# STM32U5Gx register map
File version: 1.0
CPU: CM33 r0p1, little endian, MPU, FPU, 4 interrupt priority bits
Registers are 32-bit, read-write, reset 0x0 unless marked. A register's access mark holds for its fields unless they carry their own. Offsets are from the block's base; [hi:lo] are bit positions; {n}, {i} and the like mark numbered series; 'fields as' and 'values as' point back to an identical list.

## JPEG — JPEG address block description
Base 0x4002A000
Same registers: SEC_JPEG 0x5002A000
0x00 JPEG_CONFR0 wo — JPEG codec control register
  [0] START — Start This bit start or stop the encoding or decoding process. Note: Reads always return 0.
    0=Stop/abort; 1=Start
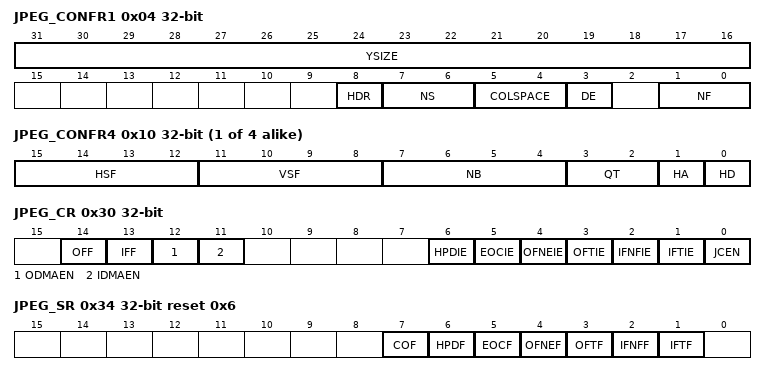
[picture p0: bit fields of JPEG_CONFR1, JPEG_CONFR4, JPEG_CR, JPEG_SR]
0x04 JPEG_CONFR1 — JPEG codec configuration register 1
  [31:16] YSIZE — Y Size This field defines the number of lines in source image.
  [8] HDR — Header processing This bit enables the header processing (generation/parsing).
    0=Disable; 1=Enable
  [7:6] NS — Number of components for scan This field defines the number of components minus 1 for scan header marker segment.
  [5:4] COLSPACE — Color space This filed defines the number of quantization tables minus 1 to insert in the output stream.
    0=Grayscale (1 quantization table); 1=YUV (2 quantization tables); 2=RGB (3 quantization tables); 3=CMYK (4 quantization tables)
  [3] DE — Codec operation as coder or decoder This bit selects the code or decode process
    0=Code; 1=Decode
  [1:0] NF — Number of color components This field defines the number of color components minus 1.
    0=Grayscale (1 color component); 1=- (2 color components); 2=YUV or RGB (3 color components); 3=CMYK (4 color components)
0x08 JPEG_CONFR2 — JPEG codec configuration register 2
  [25:0] NMCU — Number of MCUs For encoding: this field defines the number of MCU units minus 1 to encode. For decoding: this field indicates the number of complete MCU units minus 1 to be decoded (this field is updated after the JPEG header parsing). If the decoded image size has not a X or Y size multiple of 8 or 16 (depending on the sub-sampling process), the resulting incomplete or empty MCU must be added to this value to get the total number of MCUs generated.
0x0C JPEG_CONFR3 — JPEG codec configuration register 3
  [31:16] XSIZE — X size This field defines the number of pixels per line.
{0x0+4i} JPEG_CONFR{i} (i=4..7) — JPEG codec configuration register {i}
  [15:12] HSF — Horizontal sampling factor Horizontal sampling factor for component {i-4}.
  [11:8] VSF — Vertical sampling factor Vertical sampling factor for component {i-4}.
  [7:4] NB — Number of blocks Number of data units minus 1 that belong to a particular color in the MCU.
  [3:2] QT — Quantization table Selects quantization table used for component {i-4}.
    {v}=Quantization table {v} (v=0..3)
  [1] HA — Huffman AC Selects the Huffman table for encoding AC coefficients.
    0=Huffman AC table 0; 1=Huffman AC table 1
  [0] HD — Huffman DC Selects the Huffman table for encoding DC coefficients.
    0=Huffman DC table 0; 1=Huffman DC table 1
0x30 JPEG_CR access per field — JPEG control register
  [14] OFF wo — Output FIFO flush This bit flushes the output FIFO. Note: Reads always return 0.
    0=No effect; 1=Output FIFO is flushed
  [13] IFF wo — Input FIFO flush This bit flushes the input FIFO. Note: Reads always return 0.
    0=No effect; 1=Input FIFO is flushed
  [12] ODMAEN rw — Output DMA enable Enables DMA request generation for the output FIFO.
    0=Disabled; 1=Enabled
  [11] IDMAEN rw — Input DMA enable Enables DMA request generation for the input FIFO.
    0=Disabled; 1=Enabled
  [6] HPDIE rw — Header parsing done interrupt enable This bit enables interrupt generation upon the completion of the header parsing operation.
    0=Disabled; 1=Enabled
  [5] EOCIE rw — End of conversion interrupt enable This bit enables interrupt generation at the end of conversion.
    0=Disabled; 1=Enabled
  [4] OFNEIE rw — Output FIFO not empty interrupt enable This bit enables interrupt generation when the output FIFO is not empty.
    0=Disabled; 1=Enabled
  [3] OFTIE rw — Output FIFO threshold interrupt enable This bit enables interrupt generation when the output FIFO reaches a threshold.
    0=Disabled; 1=Enabled
  [2] IFNFIE rw — Input FIFO not full interrupt enable This bit enables interrupt generation when the input FIFO is not empty.
    0=Disabled; 1=Enabled
  [1] IFTIE rw — Input FIFO threshold interrupt enable This bit enables interrupt generation when the input FIFO reaches a threshold.
    0=Disabled; 1=Enabled
  [0] JCEN rw — JPEG core enable This bit enables the JPEG codec core.
    0=Disabled (internal registers are reset); 1=Enabled (internal registers are accessible)
0x34 JPEG_SR ro reset 0x6 — JPEG status register
  [7] COF — Codec operation flag This bit flags code/decode operation in progress.
    0=Not in progress; 1=In progress
  [6] HPDF — Header parsing done flag In decode mode, this bit flags the completion of header parsing and updating internal registers.
    0=Not completed; 1=Completed
  [5] EOCF — End of conversion flag This bit flags the completion of encode/decode process and data transfer to the output FIFO.
    0=Not completed; 1=Completed
  [4] OFNEF — Output FIFO not empty flag This bit flags that data is available in the output FIFO. This flag must not be considered when using DMA.
    0=Empty (data not available); 1=Not empty (data available)
  [3] OFTF — Output FIFO threshold flag This bit flags that the amount of data in the output FIFO reaches or exceeds a threshold. This flag must not be considered when using DMA.
    0=Below threshold; 1=At or above threshold
  [2] IFNFF — Input FIFO not full flag This bit flags that the input FIFO is not full (data can be written). This flag must not be considered when using DMA.
    0=Full; 1=Not full
  [1] IFTF — Input FIFO threshold flag This bit flags that the amount of data in the input FIFO is below a threshold. This flag must not be considered when using DMA.
    0=At or above threshold; 1=Below threshold
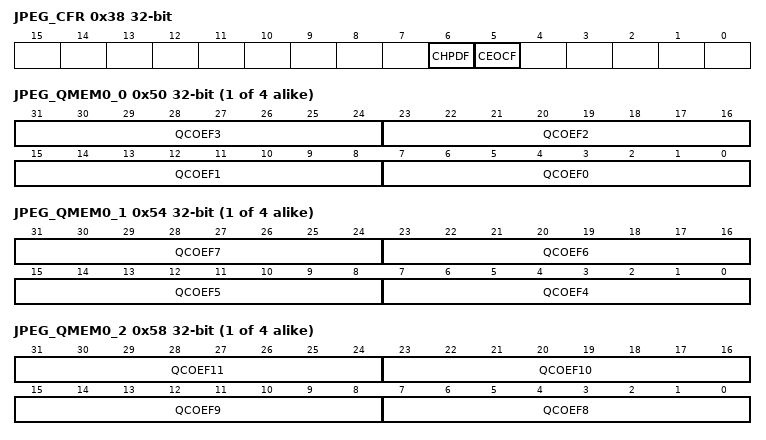
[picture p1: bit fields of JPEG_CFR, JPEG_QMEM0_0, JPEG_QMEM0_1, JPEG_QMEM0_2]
0x38 JPEG_CFR — JPEG clear flag register
  [6] CHPDF — Clear header parsing done flag Writing 1 clears the HPDF bit of the JPEG_SR register.
    0=No effect; 1=Clear
  [5] CEOCF — Clear end of conversion flag Writing 1 clears the ECF bit of the JPEG_SR register.
    0=No effect; 1=Clear
0x40 JPEG_DIR wo — JPEG data input register
  [31:0] DATAIN — Data input FIFO Input FIFO data register
0x44 JPEG_DOR ro — JPEG data output register
  [31:0] DATAOUT — Data output FIFO Output FIFO data register.
{0x50+0x40*i} JPEG_QMEM{i}_0 reset not defined (i=0..3) — JPEG quantization memory {i}
  [8n+7:8n] QCOEF{n} (n=0..3) — Quantization coefficient {n} 8-bit quantization coefficient.
{0x54+0x40*i} JPEG_QMEM{i}_1 reset not defined (i=0..3) — JPEG quantization memory {i}
  [8n-25:8n-32] QCOEF{n} (n=4..7) — Quantization coefficient {n} 8-bit quantization coefficient.
{0x58+0x40*i} JPEG_QMEM{i}_2 reset not defined (i=0..3) — JPEG quantization memory {i}
  [8n-57:8n-64] QCOEF{n} (n=8..11) — Quantization coefficient {n} 8-bit quantization coefficient.
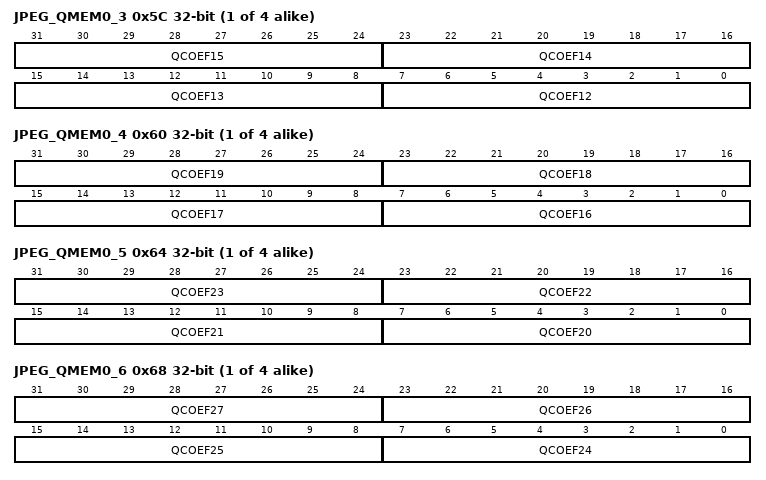
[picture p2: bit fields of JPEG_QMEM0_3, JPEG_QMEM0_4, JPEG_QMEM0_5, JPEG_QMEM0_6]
{0x5C+0x40*i} JPEG_QMEM{i}_3 reset not defined (i=0..3) — JPEG quantization memory {i}
  [8n-89:8n-96] QCOEF{n} (n=12..15) — Quantization coefficient {n} 8-bit quantization coefficient.
{0x60+0x40*i} JPEG_QMEM{i}_4 reset not defined (i=0..3) — JPEG quantization memory {i}
  [8n-121:8n-128] QCOEF{n} (n=16..19) — Quantization coefficient {n} 8-bit quantization coefficient.
{0x64+0x40*i} JPEG_QMEM{i}_5 reset not defined (i=0..3) — JPEG quantization memory {i}
  [8n-153:8n-160] QCOEF{n} (n=20..23) — Quantization coefficient {n} 8-bit quantization coefficient.
{0x68+0x40*i} JPEG_QMEM{i}_6 reset not defined (i=0..3) — JPEG quantization memory {i}
  [8n-185:8n-192] QCOEF{n} (n=24..27) — Quantization coefficient {n} 8-bit quantization coefficient.
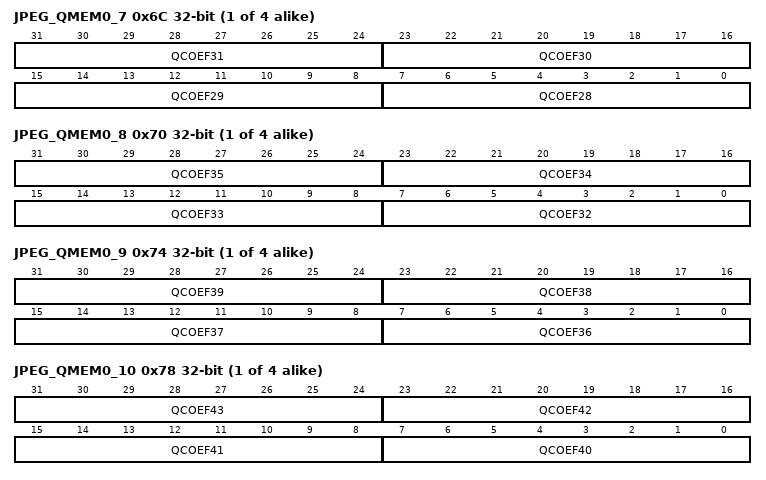
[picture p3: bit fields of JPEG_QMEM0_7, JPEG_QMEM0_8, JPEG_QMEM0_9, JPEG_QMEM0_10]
{0x6C+0x40*i} JPEG_QMEM{i}_7 reset not defined (i=0..3) — JPEG quantization memory {i}
  [8n-217:8n-224] QCOEF{n} (n=28..31) — Quantization coefficient {n} 8-bit quantization coefficient.
{0x70+0x40*i} JPEG_QMEM{i}_8 reset not defined (i=0..3) — JPEG quantization memory {i}
  [8n-249:8n-256] QCOEF{n} (n=32..35) — Quantization coefficient {n} 8-bit quantization coefficient.
{0x74+0x40*i} JPEG_QMEM{i}_9 reset not defined (i=0..3) — JPEG quantization memory {i}
  [8n-281:8n-288] QCOEF{n} (n=36..39) — Quantization coefficient {n} 8-bit quantization coefficient.
{0x78+0x40*i} JPEG_QMEM{i}_10 reset not defined (i=0..3) — JPEG quantization memory {i}
  [8n-313:8n-320] QCOEF{n} (n=40..43) — Quantization coefficient {n} 8-bit quantization coefficient.
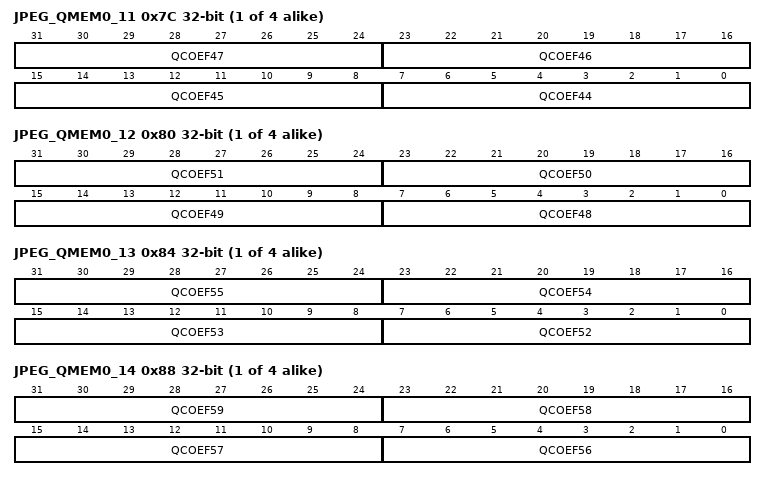
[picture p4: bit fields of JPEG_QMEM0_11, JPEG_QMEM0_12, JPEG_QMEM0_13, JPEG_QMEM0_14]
{0x7C+0x40*i} JPEG_QMEM{i}_11 reset not defined (i=0..3) — JPEG quantization memory {i}
  [8n-345:8n-352] QCOEF{n} (n=44..47) — Quantization coefficient {n} 8-bit quantization coefficient.
{0x80+0x40*i} JPEG_QMEM{i}_12 reset not defined (i=0..3) — JPEG quantization memory {i}
  [8n-377:8n-384] QCOEF{n} (n=48..51) — Quantization coefficient {n} 8-bit quantization coefficient.
{0x84+0x40*i} JPEG_QMEM{i}_13 reset not defined (i=0..3) — JPEG quantization memory {i}
  [8n-409:8n-416] QCOEF{n} (n=52..55) — Quantization coefficient {n} 8-bit quantization coefficient.
{0x88+0x40*i} JPEG_QMEM{i}_14 reset not defined (i=0..3) — JPEG quantization memory {i}
  [8n-441:8n-448] QCOEF{n} (n=56..59) — Quantization coefficient {n} 8-bit quantization coefficient.
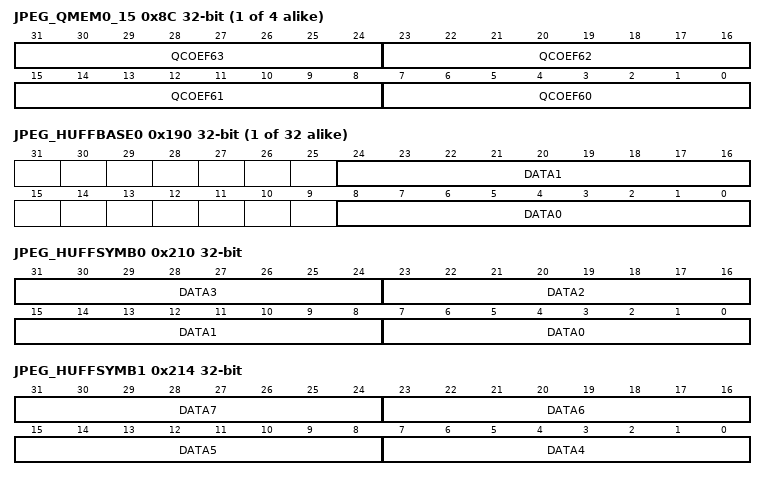
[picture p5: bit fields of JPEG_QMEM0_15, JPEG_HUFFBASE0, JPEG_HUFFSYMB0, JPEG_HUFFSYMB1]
{0x8C+0x40*i} JPEG_QMEM{i}_15 reset not defined (i=0..3) — JPEG quantization memory {i}
  [8n-473:8n-480] QCOEF{n} (n=60..63) — Quantization coefficient {n} 8-bit quantization coefficient.
{0x150+0x10*i} JPEG_HUFFMIN{i}_0 reset not defined (i=0..3) — JPEG Huffman min
  [31:0] DATA{i} — Minimum Huffman value 100-bit minimum Huffman value used internally by the JPEG decoder.
{0x154+0x10*i} JPEG_HUFFMIN{i}_1 reset not defined (i=0..3) — JPEG Huffman min
  fields as JPEG_HUFFMIN0_0
{0x158+0x10*i} JPEG_HUFFMIN{i}_2 reset not defined (i=0..3) — JPEG Huffman min
  fields as JPEG_HUFFMIN0_0
{0x15C+0x10*i} JPEG_HUFFMIN{i}_3 reset not defined (i=0..3) — JPEG Huffman min {i} [alternate]
  [3:0] DATA{i} — Minimum Huffman value 100-bit minimum Huffman value used internally by the JPEG decoder.
{0x190+4i} JPEG_HUFFBASE{i} reset not defined (i=0..31) — JPEG Huffman base
  [24:16] DATA{2i+1} — Data {2i+1} Base Huffman value.
  [8:0] DATA{2i} — Data {2i} Base Huffman value.
0x210 JPEG_HUFFSYMB0 reset not defined — JPEG Huffman symbol
  [8n+7:8n] DATA{n} (n=0..3) — Data {n} Huffman symbol.
0x214 JPEG_HUFFSYMB1 reset not defined — JPEG Huffman symbol
  [8n-25:8n-32] DATA{n} (n=4..7) — Data {n} Huffman symbol.
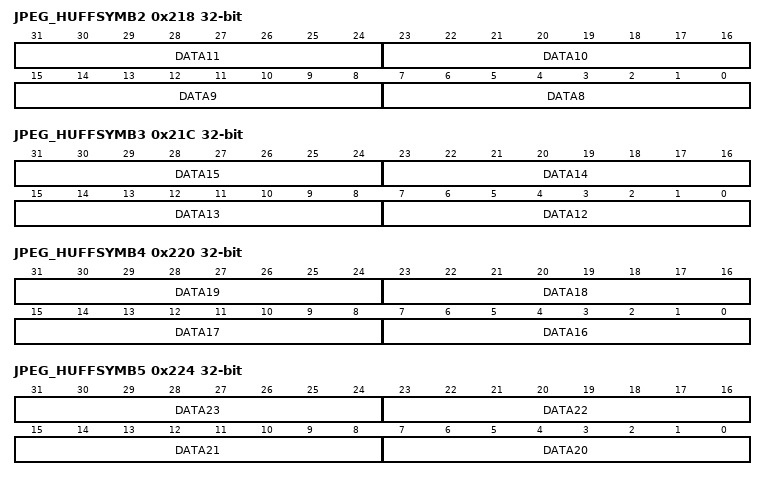
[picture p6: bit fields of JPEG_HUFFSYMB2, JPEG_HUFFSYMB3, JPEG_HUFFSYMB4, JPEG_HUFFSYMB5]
0x218 JPEG_HUFFSYMB2 reset not defined — JPEG Huffman symbol
  [8n-57:8n-64] DATA{n} (n=8..11) — Data {n} Huffman symbol.
0x21C JPEG_HUFFSYMB3 reset not defined — JPEG Huffman symbol
  [8n-89:8n-96] DATA{n} (n=12..15) — Data {n} Huffman symbol.
0x220 JPEG_HUFFSYMB4 reset not defined — JPEG Huffman symbol
  [8n-121:8n-128] DATA{n} (n=16..19) — Data {n} Huffman symbol.
0x224 JPEG_HUFFSYMB5 reset not defined — JPEG Huffman symbol
  [8n-153:8n-160] DATA{n} (n=20..23) — Data {n} Huffman symbol.
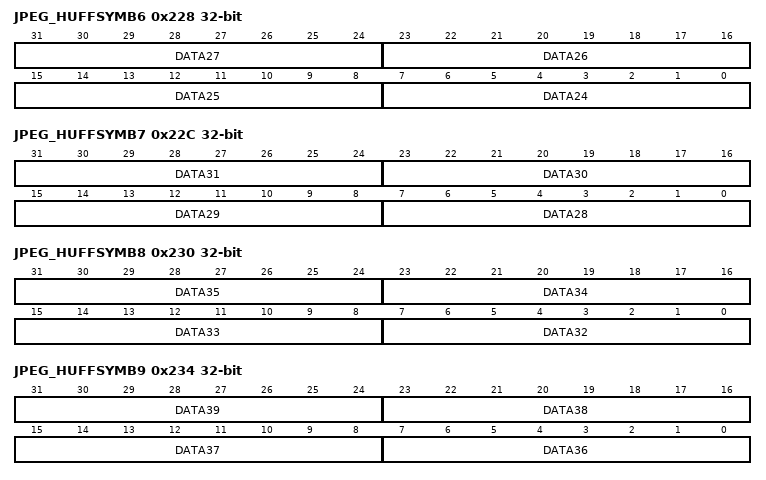
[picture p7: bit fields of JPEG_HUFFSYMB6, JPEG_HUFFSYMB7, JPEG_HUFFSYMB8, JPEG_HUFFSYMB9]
0x228 JPEG_HUFFSYMB6 reset not defined — JPEG Huffman symbol
  [8n-185:8n-192] DATA{n} (n=24..27) — Data {n} Huffman symbol.
0x22C JPEG_HUFFSYMB7 reset not defined — JPEG Huffman symbol
  [8n-217:8n-224] DATA{n} (n=28..31) — Data {n} Huffman symbol.
0x230 JPEG_HUFFSYMB8 reset not defined — JPEG Huffman symbol
  [8n-249:8n-256] DATA{n} (n=32..35) — Data {n} Huffman symbol.
0x234 JPEG_HUFFSYMB9 reset not defined — JPEG Huffman symbol
  [8n-281:8n-288] DATA{n} (n=36..39) — Data {n} Huffman symbol.
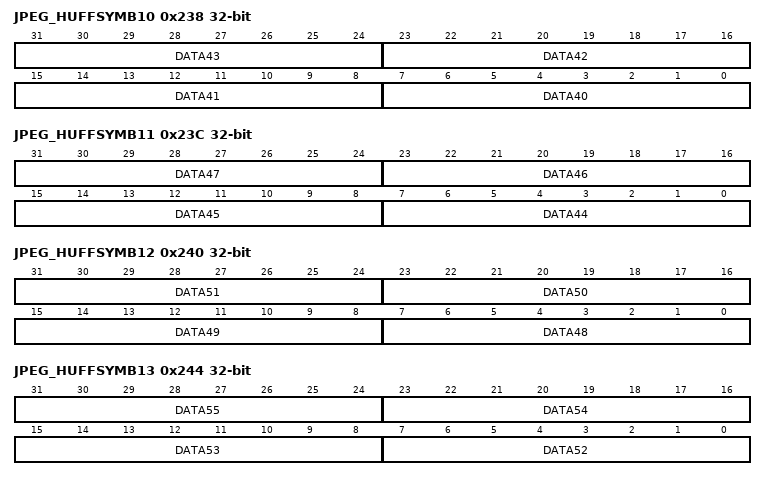
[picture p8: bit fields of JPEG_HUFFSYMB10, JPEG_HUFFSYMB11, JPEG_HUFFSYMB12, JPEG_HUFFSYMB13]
0x238 JPEG_HUFFSYMB10 reset not defined — JPEG Huffman symbol
  [8n-313:8n-320] DATA{n} (n=40..43) — Data {n} Huffman symbol.
0x23C JPEG_HUFFSYMB11 reset not defined — JPEG Huffman symbol
  [8n-345:8n-352] DATA{n} (n=44..47) — Data {n} Huffman symbol.
0x240 JPEG_HUFFSYMB12 reset not defined — JPEG Huffman symbol
  [8n-377:8n-384] DATA{n} (n=48..51) — Data {n} Huffman symbol.
0x244 JPEG_HUFFSYMB13 reset not defined — JPEG Huffman symbol
  [8n-409:8n-416] DATA{n} (n=52..55) — Data {n} Huffman symbol.
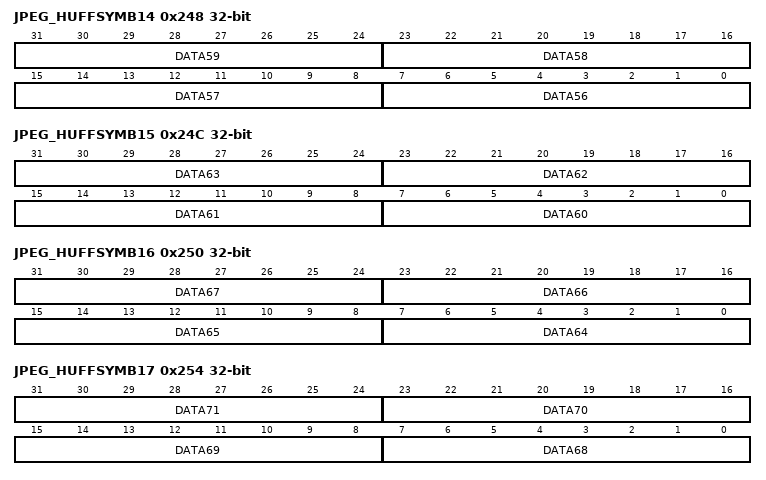
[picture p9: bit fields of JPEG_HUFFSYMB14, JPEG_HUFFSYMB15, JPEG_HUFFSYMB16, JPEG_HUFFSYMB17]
0x248 JPEG_HUFFSYMB14 reset not defined — JPEG Huffman symbol
  [8n-441:8n-448] DATA{n} (n=56..59) — Data {n} Huffman symbol.
0x24C JPEG_HUFFSYMB15 reset not defined — JPEG Huffman symbol
  [8n-473:8n-480] DATA{n} (n=60..63) — Data {n} Huffman symbol.
0x250 JPEG_HUFFSYMB16 reset not defined — JPEG Huffman symbol
  [8n-505:8n-512] DATA{n} (n=64..67) — Data {n} Huffman symbol.
0x254 JPEG_HUFFSYMB17 reset not defined — JPEG Huffman symbol
  [8n-537:8n-544] DATA{n} (n=68..71) — Data {n} Huffman symbol.
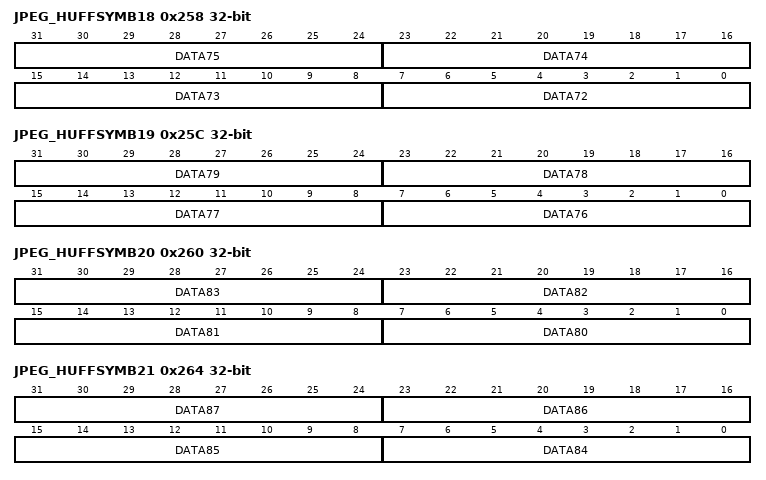
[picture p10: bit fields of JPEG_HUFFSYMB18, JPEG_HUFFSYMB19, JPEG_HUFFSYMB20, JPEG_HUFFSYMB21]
0x258 JPEG_HUFFSYMB18 reset not defined — JPEG Huffman symbol
  [8n-569:8n-576] DATA{n} (n=72..75) — Data {n} Huffman symbol.
0x25C JPEG_HUFFSYMB19 reset not defined — JPEG Huffman symbol
  [8n-601:8n-608] DATA{n} (n=76..79) — Data {n} Huffman symbol.
0x260 JPEG_HUFFSYMB20 reset not defined — JPEG Huffman symbol
  [8n-633:8n-640] DATA{n} (n=80..83) — Data {n} Huffman symbol.
0x264 JPEG_HUFFSYMB21 reset not defined — JPEG Huffman symbol
  [8n-665:8n-672] DATA{n} (n=84..87) — Data {n} Huffman symbol.
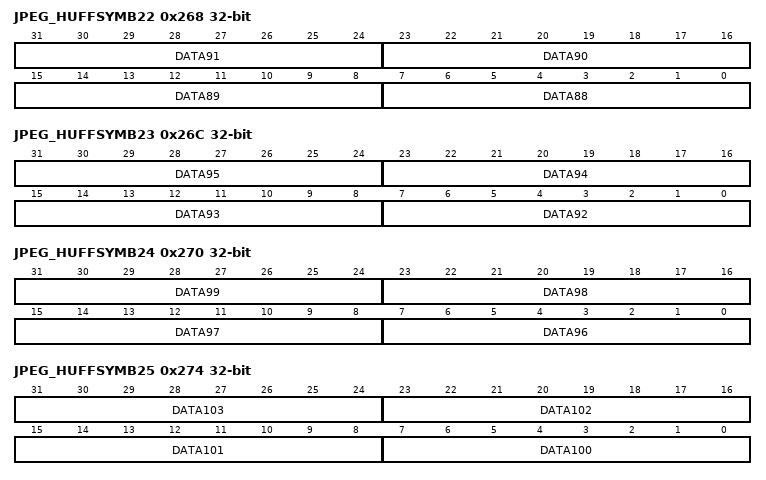
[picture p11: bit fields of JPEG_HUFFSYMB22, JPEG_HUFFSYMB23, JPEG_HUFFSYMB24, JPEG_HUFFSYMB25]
0x268 JPEG_HUFFSYMB22 reset not defined — JPEG Huffman symbol
  [8n-697:8n-704] DATA{n} (n=88..91) — Data {n} Huffman symbol.
0x26C JPEG_HUFFSYMB23 reset not defined — JPEG Huffman symbol
  [8n-729:8n-736] DATA{n} (n=92..95) — Data {n} Huffman symbol.
0x270 JPEG_HUFFSYMB24 reset not defined — JPEG Huffman symbol
  [8n-761:8n-768] DATA{n} (n=96..99) — Data {n} Huffman symbol.
0x274 JPEG_HUFFSYMB25 reset not defined — JPEG Huffman symbol
  [8n-793:8n-800] DATA{n} (n=100..103) — Data {n} Huffman symbol.
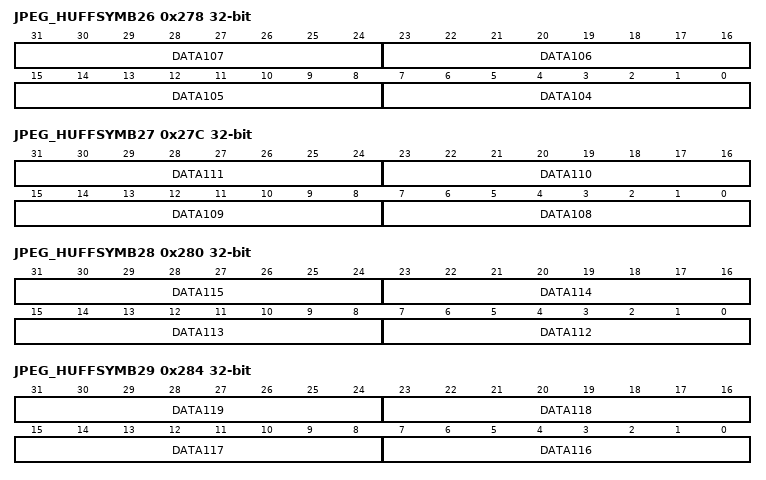
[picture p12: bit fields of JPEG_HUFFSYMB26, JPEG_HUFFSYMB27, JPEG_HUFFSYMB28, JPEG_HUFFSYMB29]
0x278 JPEG_HUFFSYMB26 reset not defined — JPEG Huffman symbol
  [8n-825:8n-832] DATA{n} (n=104..107) — Data {n} Huffman symbol.
0x27C JPEG_HUFFSYMB27 reset not defined — JPEG Huffman symbol
  [8n-857:8n-864] DATA{n} (n=108..111) — Data {n} Huffman symbol.
0x280 JPEG_HUFFSYMB28 reset not defined — JPEG Huffman symbol
  [8n-889:8n-896] DATA{n} (n=112..115) — Data {n} Huffman symbol.
0x284 JPEG_HUFFSYMB29 reset not defined — JPEG Huffman symbol
  [8n-921:8n-928] DATA{n} (n=116..119) — Data {n} Huffman symbol.
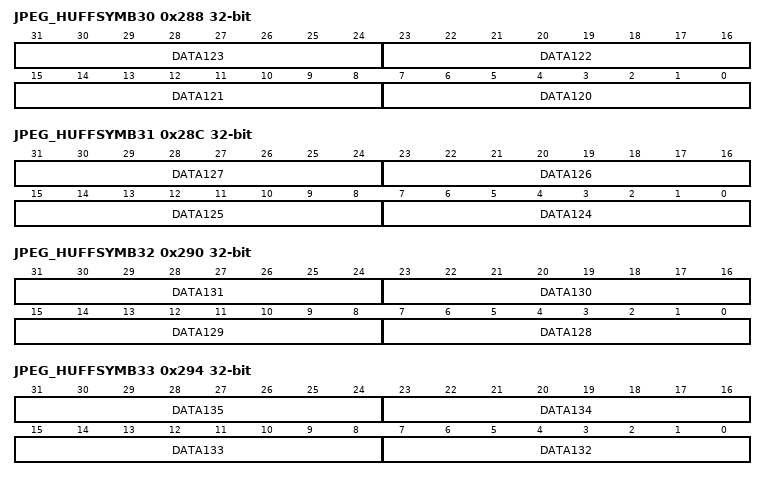
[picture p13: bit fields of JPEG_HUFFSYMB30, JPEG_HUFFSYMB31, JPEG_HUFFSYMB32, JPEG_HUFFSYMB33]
0x288 JPEG_HUFFSYMB30 reset not defined — JPEG Huffman symbol
  [8n-953:8n-960] DATA{n} (n=120..123) — Data {n} Huffman symbol.
0x28C JPEG_HUFFSYMB31 reset not defined — JPEG Huffman symbol
  [8n-985:8n-992] DATA{n} (n=124..127) — Data {n} Huffman symbol.
0x290 JPEG_HUFFSYMB32 reset not defined — JPEG Huffman symbol
  [8n-1017:8n-1024] DATA{n} (n=128..131) — Data {n} Huffman symbol.
0x294 JPEG_HUFFSYMB33 reset not defined — JPEG Huffman symbol
  [8n-1049:8n-1056] DATA{n} (n=132..135) — Data {n} Huffman symbol.
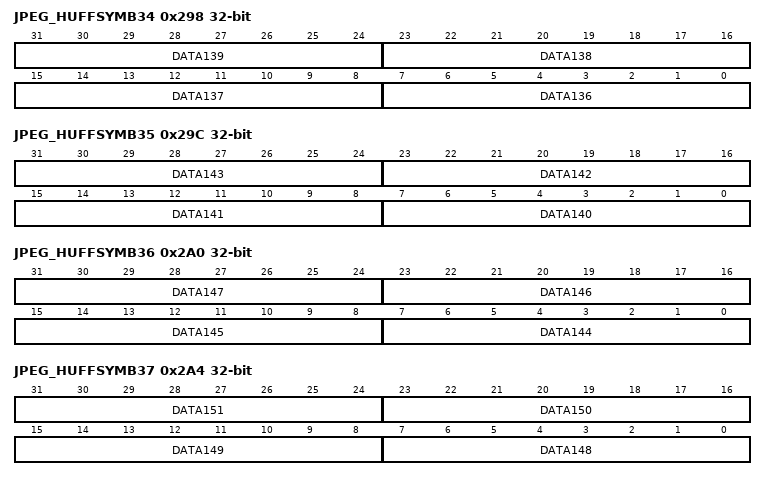
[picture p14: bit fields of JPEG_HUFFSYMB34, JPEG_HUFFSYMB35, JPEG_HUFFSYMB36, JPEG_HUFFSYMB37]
0x298 JPEG_HUFFSYMB34 reset not defined — JPEG Huffman symbol
  [8n-1081:8n-1088] DATA{n} (n=136..139) — Data {n} Huffman symbol.
0x29C JPEG_HUFFSYMB35 reset not defined — JPEG Huffman symbol
  [8n-1113:8n-1120] DATA{n} (n=140..143) — Data {n} Huffman symbol.
0x2A0 JPEG_HUFFSYMB36 reset not defined — JPEG Huffman symbol
  [8n-1145:8n-1152] DATA{n} (n=144..147) — Data {n} Huffman symbol.
0x2A4 JPEG_HUFFSYMB37 reset not defined — JPEG Huffman symbol
  [8n-1177:8n-1184] DATA{n} (n=148..151) — Data {n} Huffman symbol.
0x2A8 JPEG_HUFFSYMB38 reset not defined — JPEG Huffman symbol
  [8n-1209:8n-1216] DATA{n} (n=152..155) — Data {n} Huffman symbol.
0x2AC JPEG_HUFFSYMB39 reset not defined — JPEG Huffman symbol
  [8n-1241:8n-1248] DATA{n} (n=156..159) — Data {n} Huffman symbol.
0x2B0 JPEG_HUFFSYMB40 reset not defined — JPEG Huffman symbol
  [8n-1273:8n-1280] DATA{n} (n=160..163) — Data {n} Huffman symbol.
0x2B4 JPEG_HUFFSYMB41 reset not defined — JPEG Huffman symbol
  [8n-1305:8n-1312] DATA{n} (n=164..167) — Data {n} Huffman symbol.
0x2B8 JPEG_HUFFSYMB42 reset not defined — JPEG Huffman symbol
  [8n-1337:8n-1344] DATA{n} (n=168..171) — Data {n} Huffman symbol.
0x2BC JPEG_HUFFSYMB43 reset not defined — JPEG Huffman symbol
  [8n-1369:8n-1376] DATA{n} (n=172..175) — Data {n} Huffman symbol.
0x2C0 JPEG_HUFFSYMB44 reset not defined — JPEG Huffman symbol
  [8n-1401:8n-1408] DATA{n} (n=176..179) — Data {n} Huffman symbol.
0x2C4 JPEG_HUFFSYMB45 reset not defined — JPEG Huffman symbol
  [8n-1433:8n-1440] DATA{n} (n=180..183) — Data {n} Huffman symbol.
0x2C8 JPEG_HUFFSYMB46 reset not defined — JPEG Huffman symbol
  [8n-1465:8n-1472] DATA{n} (n=184..187) — Data {n} Huffman symbol.
0x2CC JPEG_HUFFSYMB47 reset not defined — JPEG Huffman symbol
  [8n-1497:8n-1504] DATA{n} (n=188..191) — Data {n} Huffman symbol.
0x2D0 JPEG_HUFFSYMB48 reset not defined — JPEG Huffman symbol
  [8n-1529:8n-1536] DATA{n} (n=192..195) — Data {n} Huffman symbol.
0x2D4 JPEG_HUFFSYMB49 reset not defined — JPEG Huffman symbol
  [8n-1561:8n-1568] DATA{n} (n=196..199) — Data {n} Huffman symbol.
0x2D8 JPEG_HUFFSYMB50 reset not defined — JPEG Huffman symbol
  [8n-1593:8n-1600] DATA{n} (n=200..203) — Data {n} Huffman symbol.
0x2DC JPEG_HUFFSYMB51 reset not defined — JPEG Huffman symbol
  [8n-1625:8n-1632] DATA{n} (n=204..207) — Data {n} Huffman symbol.
0x2E0 JPEG_HUFFSYMB52 reset not defined — JPEG Huffman symbol
  [8n-1657:8n-1664] DATA{n} (n=208..211) — Data {n} Huffman symbol.
0x2E4 JPEG_HUFFSYMB53 reset not defined — JPEG Huffman symbol
  [8n-1689:8n-1696] DATA{n} (n=212..215) — Data {n} Huffman symbol.
0x2E8 JPEG_HUFFSYMB54 reset not defined — JPEG Huffman symbol
  [8n-1721:8n-1728] DATA{n} (n=216..219) — Data {n} Huffman symbol.
0x2EC JPEG_HUFFSYMB55 reset not defined — JPEG Huffman symbol
  [8n-1753:8n-1760] DATA{n} (n=220..223) — Data {n} Huffman symbol.
0x2F0 JPEG_HUFFSYMB56 reset not defined — JPEG Huffman symbol
  [8n-1785:8n-1792] DATA{n} (n=224..227) — Data {n} Huffman symbol.
0x2F4 JPEG_HUFFSYMB57 reset not defined — JPEG Huffman symbol
  [8n-1817:8n-1824] DATA{n} (n=228..231) — Data {n} Huffman symbol.
0x2F8 JPEG_HUFFSYMB58 reset not defined — JPEG Huffman symbol
  [8n-1849:8n-1856] DATA{n} (n=232..235) — Data {n} Huffman symbol.
0x2FC JPEG_HUFFSYMB59 reset not defined — JPEG Huffman symbol
  [8n-1881:8n-1888] DATA{n} (n=236..239) — Data {n} Huffman symbol.
0x300 JPEG_HUFFSYMB60 reset not defined — JPEG Huffman symbol
  [8n-1913:8n-1920] DATA{n} (n=240..243) — Data {n} Huffman symbol.
0x304 JPEG_HUFFSYMB61 reset not defined — JPEG Huffman symbol
  [8n-1945:8n-1952] DATA{n} (n=244..247) — Data {n} Huffman symbol.
0x308 JPEG_HUFFSYMB62 reset not defined — JPEG Huffman symbol
  [8n-1977:8n-1984] DATA{n} (n=248..251) — Data {n} Huffman symbol.
0x30C JPEG_HUFFSYMB63 reset not defined — JPEG Huffman symbol
  [8n-2009:8n-2016] DATA{n} (n=252..255) — Data {n} Huffman symbol.
0x310 JPEG_HUFFSYMB64 reset not defined — JPEG Huffman symbol
  [8n-2041:8n-2048] DATA{n} (n=256..259) — Data {n} Huffman symbol.
0x314 JPEG_HUFFSYMB65 reset not defined — JPEG Huffman symbol
  [8n-2073:8n-2080] DATA{n} (n=260..263) — Data {n} Huffman symbol.
0x318 JPEG_HUFFSYMB66 reset not defined — JPEG Huffman symbol
  [8n-2105:8n-2112] DATA{n} (n=264..267) — Data {n} Huffman symbol.
0x31C JPEG_HUFFSYMB67 reset not defined — JPEG Huffman symbol
  [8n-2137:8n-2144] DATA{n} (n=268..271) — Data {n} Huffman symbol.
0x320 JPEG_HUFFSYMB68 reset not defined — JPEG Huffman symbol
  [8n-2169:8n-2176] DATA{n} (n=272..275) — Data {n} Huffman symbol.
0x324 JPEG_HUFFSYMB69 reset not defined — JPEG Huffman symbol
  [8n-2201:8n-2208] DATA{n} (n=276..279) — Data {n} Huffman symbol.
0x328 JPEG_HUFFSYMB70 reset not defined — JPEG Huffman symbol
  [8n-2233:8n-2240] DATA{n} (n=280..283) — Data {n} Huffman symbol.
0x32C JPEG_HUFFSYMB71 reset not defined — JPEG Huffman symbol
  [8n-2265:8n-2272] DATA{n} (n=284..287) — Data {n} Huffman symbol.
0x330 JPEG_HUFFSYMB72 reset not defined — JPEG Huffman symbol
  [8n-2297:8n-2304] DATA{n} (n=288..291) — Data {n} Huffman symbol.
0x334 JPEG_HUFFSYMB73 reset not defined — JPEG Huffman symbol
  [8n-2329:8n-2336] DATA{n} (n=292..295) — Data {n} Huffman symbol.
0x338 JPEG_HUFFSYMB74 reset not defined — JPEG Huffman symbol
  [8n-2361:8n-2368] DATA{n} (n=296..299) — Data {n} Huffman symbol.
0x33C JPEG_HUFFSYMB75 reset not defined — JPEG Huffman symbol
  [8n-2393:8n-2400] DATA{n} (n=300..303) — Data {n} Huffman symbol.
0x340 JPEG_HUFFSYMB76 reset not defined — JPEG Huffman symbol
  [8n-2425:8n-2432] DATA{n} (n=304..307) — Data {n} Huffman symbol.
0x344 JPEG_HUFFSYMB77 reset not defined — JPEG Huffman symbol
  [8n-2457:8n-2464] DATA{n} (n=308..311) — Data {n} Huffman symbol.
0x348 JPEG_HUFFSYMB78 reset not defined — JPEG Huffman symbol
  [8n-2489:8n-2496] DATA{n} (n=312..315) — Data {n} Huffman symbol.
0x34C JPEG_HUFFSYMB79 reset not defined — JPEG Huffman symbol
  [8n-2521:8n-2528] DATA{n} (n=316..319) — Data {n} Huffman symbol.
0x350 JPEG_HUFFSYMB80 reset not defined — JPEG Huffman symbol
  [8n-2553:8n-2560] DATA{n} (n=320..323) — Data {n} Huffman symbol.
0x354 JPEG_HUFFSYMB81 reset not defined — JPEG Huffman symbol
  [8n-2585:8n-2592] DATA{n} (n=324..327) — Data {n} Huffman symbol.
0x358 JPEG_HUFFSYMB82 reset not defined — JPEG Huffman symbol
  [8n-2617:8n-2624] DATA{n} (n=328..331) — Data {n} Huffman symbol.
0x35C JPEG_HUFFSYMB83 reset not defined — JPEG Huffman symbol
  [8n-2649:8n-2656] DATA{n} (n=332..335) — Data {n} Huffman symbol.
0x360 JPEG_DHTMEM0 reset not defined — JPEG DHT memory
  [8n+7:8n] DATA{n} (n=0..3) — Huffman table data {n} Huffman table data for DHT marker segment generation.
0x364 JPEG_DHTMEM1 reset not defined — JPEG DHT memory
  [8n-25:8n-32] DATA{n} (n=4..7) — Huffman table data {n} Huffman table data for DHT marker segment generation.
0x368 JPEG_DHTMEM2 reset not defined — JPEG DHT memory
  [8n-57:8n-64] DATA{n} (n=8..11) — Huffman table data {n} Huffman table data for DHT marker segment generation.
0x36C JPEG_DHTMEM3 reset not defined — JPEG DHT memory
  [8n-89:8n-96] DATA{n} (n=12..15) — Huffman table data {n} Huffman table data for DHT marker segment generation.
0x370 JPEG_DHTMEM4 reset not defined — JPEG DHT memory
  [8n-121:8n-128] DATA{n} (n=16..19) — Huffman table data {n} Huffman table data for DHT marker segment generation.
0x374 JPEG_DHTMEM5 reset not defined — JPEG DHT memory
  [8n-153:8n-160] DATA{n} (n=20..23) — Huffman table data {n} Huffman table data for DHT marker segment generation.
0x378 JPEG_DHTMEM6 reset not defined — JPEG DHT memory
  [8n-185:8n-192] DATA{n} (n=24..27) — Huffman table data {n} Huffman table data for DHT marker segment generation.
0x37C JPEG_DHTMEM7 reset not defined — JPEG DHT memory
  [8n-217:8n-224] DATA{n} (n=28..31) — Huffman table data {n} Huffman table data for DHT marker segment generation.
0x380 JPEG_DHTMEM8 reset not defined — JPEG DHT memory
  [8n-249:8n-256] DATA{n} (n=32..35) — Huffman table data {n} Huffman table data for DHT marker segment generation.
0x384 JPEG_DHTMEM9 reset not defined — JPEG DHT memory
  [8n-281:8n-288] DATA{n} (n=36..39) — Huffman table data {n} Huffman table data for DHT marker segment generation.
0x388 JPEG_DHTMEM10 reset not defined — JPEG DHT memory
  [8n-313:8n-320] DATA{n} (n=40..43) — Huffman table data {n} Huffman table data for DHT marker segment generation.
0x38C JPEG_DHTMEM11 reset not defined — JPEG DHT memory
  [8n-345:8n-352] DATA{n} (n=44..47) — Huffman table data {n} Huffman table data for DHT marker segment generation.
0x390 JPEG_DHTMEM12 reset not defined — JPEG DHT memory
  [8n-377:8n-384] DATA{n} (n=48..51) — Huffman table data {n} Huffman table data for DHT marker segment generation.
0x394 JPEG_DHTMEM13 reset not defined — JPEG DHT memory
  [8n-409:8n-416] DATA{n} (n=52..55) — Huffman table data {n} Huffman table data for DHT marker segment generation.
0x398 JPEG_DHTMEM14 reset not defined — JPEG DHT memory
  [8n-441:8n-448] DATA{n} (n=56..59) — Huffman table data {n} Huffman table data for DHT marker segment generation.
0x39C JPEG_DHTMEM15 reset not defined — JPEG DHT memory
  [8n-473:8n-480] DATA{n} (n=60..63) — Huffman table data {n} Huffman table data for DHT marker segment generation.
0x3A0 JPEG_DHTMEM16 reset not defined — JPEG DHT memory
  [8n-505:8n-512] DATA{n} (n=64..67) — Huffman table data {n} Huffman table data for DHT marker segment generation.
0x3A4 JPEG_DHTMEM17 reset not defined — JPEG DHT memory
  [8n-537:8n-544] DATA{n} (n=68..71) — Huffman table data {n} Huffman table data for DHT marker segment generation.
0x3A8 JPEG_DHTMEM18 reset not defined — JPEG DHT memory
  [8n-569:8n-576] DATA{n} (n=72..75) — Huffman table data {n} Huffman table data for DHT marker segment generation.
0x3AC JPEG_DHTMEM19 reset not defined — JPEG DHT memory
  [8n-601:8n-608] DATA{n} (n=76..79) — Huffman table data {n} Huffman table data for DHT marker segment generation.
0x3B0 JPEG_DHTMEM20 reset not defined — JPEG DHT memory
  [8n-633:8n-640] DATA{n} (n=80..83) — Huffman table data {n} Huffman table data for DHT marker segment generation.
0x3B4 JPEG_DHTMEM21 reset not defined — JPEG DHT memory
  [8n-665:8n-672] DATA{n} (n=84..87) — Huffman table data {n} Huffman table data for DHT marker segment generation.
0x3B8 JPEG_DHTMEM22 reset not defined — JPEG DHT memory
  [8n-697:8n-704] DATA{n} (n=88..91) — Huffman table data {n} Huffman table data for DHT marker segment generation.
0x3BC JPEG_DHTMEM23 reset not defined — JPEG DHT memory
  [8n-729:8n-736] DATA{n} (n=92..95) — Huffman table data {n} Huffman table data for DHT marker segment generation.
0x3C0 JPEG_DHTMEM24 reset not defined — JPEG DHT memory
  [8n-761:8n-768] DATA{n} (n=96..99) — Huffman table data {n} Huffman table data for DHT marker segment generation.
0x3C4 JPEG_DHTMEM25 reset not defined — JPEG DHT memory
  [8n-793:8n-800] DATA{n} (n=100..103) — Huffman table data {n} Huffman table data for DHT marker segment generation.
0x3C8 JPEG_DHTMEM26 reset not defined — JPEG DHT memory
  [8n-825:8n-832] DATA{n} (n=104..107) — Huffman table data {n} Huffman table data for DHT marker segment generation.
0x3CC JPEG_DHTMEM27 reset not defined — JPEG DHT memory
  [8n-857:8n-864] DATA{n} (n=108..111) — Huffman table data {n} Huffman table data for DHT marker segment generation.
0x3D0 JPEG_DHTMEM28 reset not defined — JPEG DHT memory
  [8n-889:8n-896] DATA{n} (n=112..115) — Huffman table data {n} Huffman table data for DHT marker segment generation.
0x3D4 JPEG_DHTMEM29 reset not defined — JPEG DHT memory
  [8n-921:8n-928] DATA{n} (n=116..119) — Huffman table data {n} Huffman table data for DHT marker segment generation.
0x3D8 JPEG_DHTMEM30 reset not defined — JPEG DHT memory
  [8n-953:8n-960] DATA{n} (n=120..123) — Huffman table data {n} Huffman table data for DHT marker segment generation.
0x3DC JPEG_DHTMEM31 reset not defined — JPEG DHT memory
  [8n-985:8n-992] DATA{n} (n=124..127) — Huffman table data {n} Huffman table data for DHT marker segment generation.
0x3E0 JPEG_DHTMEM32 reset not defined — JPEG DHT memory
  [8n-1017:8n-1024] DATA{n} (n=128..131) — Huffman table data {n} Huffman table data for DHT marker segment generation.
0x3E4 JPEG_DHTMEM33 reset not defined — JPEG DHT memory
  [8n-1049:8n-1056] DATA{n} (n=132..135) — Huffman table data {n} Huffman table data for DHT marker segment generation.
0x3E8 JPEG_DHTMEM34 reset not defined — JPEG DHT memory
  [8n-1081:8n-1088] DATA{n} (n=136..139) — Huffman table data {n} Huffman table data for DHT marker segment generation.
0x3EC JPEG_DHTMEM35 reset not defined — JPEG DHT memory
  [8n-1113:8n-1120] DATA{n} (n=140..143) — Huffman table data {n} Huffman table data for DHT marker segment generation.
0x3F0 JPEG_DHTMEM36 reset not defined — JPEG DHT memory
  [8n-1145:8n-1152] DATA{n} (n=144..147) — Huffman table data {n} Huffman table data for DHT marker segment generation.
0x3F4 JPEG_DHTMEM37 reset not defined — JPEG DHT memory
  [8n-1177:8n-1184] DATA{n} (n=148..151) — Huffman table data {n} Huffman table data for DHT marker segment generation.
0x3F8 JPEG_DHTMEM38 reset not defined — JPEG DHT memory
  [8n-1209:8n-1216] DATA{n} (n=152..155) — Huffman table data {n} Huffman table data for DHT marker segment generation.
0x3FC JPEG_DHTMEM39 reset not defined — JPEG DHT memory
  [8n-1241:8n-1248] DATA{n} (n=156..159) — Huffman table data {n} Huffman table data for DHT marker segment generation.
0x400 JPEG_DHTMEM40 reset not defined — JPEG DHT memory
  [8n-1273:8n-1280] DATA{n} (n=160..163) — Huffman table data {n} Huffman table data for DHT marker segment generation.
0x404 JPEG_DHTMEM41 reset not defined — JPEG DHT memory
  [8n-1305:8n-1312] DATA{n} (n=164..167) — Huffman table data {n} Huffman table data for DHT marker segment generation.
0x408 JPEG_DHTMEM42 reset not defined — JPEG DHT memory
  [8n-1337:8n-1344] DATA{n} (n=168..171) — Huffman table data {n} Huffman table data for DHT marker segment generation.
0x40C JPEG_DHTMEM43 reset not defined — JPEG DHT memory
  [8n-1369:8n-1376] DATA{n} (n=172..175) — Huffman table data {n} Huffman table data for DHT marker segment generation.
0x410 JPEG_DHTMEM44 reset not defined — JPEG DHT memory
  [8n-1401:8n-1408] DATA{n} (n=176..179) — Huffman table data {n} Huffman table data for DHT marker segment generation.
0x414 JPEG_DHTMEM45 reset not defined — JPEG DHT memory
  [8n-1433:8n-1440] DATA{n} (n=180..183) — Huffman table data {n} Huffman table data for DHT marker segment generation.
0x418 JPEG_DHTMEM46 reset not defined — JPEG DHT memory
  [8n-1465:8n-1472] DATA{n} (n=184..187) — Huffman table data {n} Huffman table data for DHT marker segment generation.
0x41C JPEG_DHTMEM47 reset not defined — JPEG DHT memory
  [8n-1497:8n-1504] DATA{n} (n=188..191) — Huffman table data {n} Huffman table data for DHT marker segment generation.
0x420 JPEG_DHTMEM48 reset not defined — JPEG DHT memory
  [8n-1529:8n-1536] DATA{n} (n=192..195) — Huffman table data {n} Huffman table data for DHT marker segment generation.
0x424 JPEG_DHTMEM49 reset not defined — JPEG DHT memory
  [8n-1561:8n-1568] DATA{n} (n=196..199) — Huffman table data {n} Huffman table data for DHT marker segment generation.
0x428 JPEG_DHTMEM50 reset not defined — JPEG DHT memory
  [8n-1593:8n-1600] DATA{n} (n=200..203) — Huffman table data {n} Huffman table data for DHT marker segment generation.
0x42C JPEG_DHTMEM51 reset not defined — JPEG DHT memory
  [8n-1625:8n-1632] DATA{n} (n=204..207) — Huffman table data {n} Huffman table data for DHT marker segment generation.
0x430 JPEG_DHTMEM52 reset not defined — JPEG DHT memory
  [8n-1657:8n-1664] DATA{n} (n=208..211) — Huffman table data {n} Huffman table data for DHT marker segment generation.
0x434 JPEG_DHTMEM53 reset not defined — JPEG DHT memory
  [8n-1689:8n-1696] DATA{n} (n=212..215) — Huffman table data {n} Huffman table data for DHT marker segment generation.
0x438 JPEG_DHTMEM54 reset not defined — JPEG DHT memory
  [8n-1721:8n-1728] DATA{n} (n=216..219) — Huffman table data {n} Huffman table data for DHT marker segment generation.
0x43C JPEG_DHTMEM55 reset not defined — JPEG DHT memory
  [8n-1753:8n-1760] DATA{n} (n=220..223) — Huffman table data {n} Huffman table data for DHT marker segment generation.
0x440 JPEG_DHTMEM56 reset not defined — JPEG DHT memory
  [8n-1785:8n-1792] DATA{n} (n=224..227) — Huffman table data {n} Huffman table data for DHT marker segment generation.
0x444 JPEG_DHTMEM57 reset not defined — JPEG DHT memory
  [8n-1817:8n-1824] DATA{n} (n=228..231) — Huffman table data {n} Huffman table data for DHT marker segment generation.
0x448 JPEG_DHTMEM58 reset not defined — JPEG DHT memory
  [8n-1849:8n-1856] DATA{n} (n=232..235) — Huffman table data {n} Huffman table data for DHT marker segment generation.
0x44C JPEG_DHTMEM59 reset not defined — JPEG DHT memory
  [8n-1881:8n-1888] DATA{n} (n=236..239) — Huffman table data {n} Huffman table data for DHT marker segment generation.
0x450 JPEG_DHTMEM60 reset not defined — JPEG DHT memory
  [8n-1913:8n-1920] DATA{n} (n=240..243) — Huffman table data {n} Huffman table data for DHT marker segment generation.
0x454 JPEG_DHTMEM61 reset not defined — JPEG DHT memory
  [8n-1945:8n-1952] DATA{n} (n=244..247) — Huffman table data {n} Huffman table data for DHT marker segment generation.
0x458 JPEG_DHTMEM62 reset not defined — JPEG DHT memory
  [8n-1977:8n-1984] DATA{n} (n=248..251) — Huffman table data {n} Huffman table data for DHT marker segment generation.
0x45C JPEG_DHTMEM63 reset not defined — JPEG DHT memory
  [8n-2009:8n-2016] DATA{n} (n=252..255) — Huffman table data {n} Huffman table data for DHT marker segment generation.
0x460 JPEG_DHTMEM64 reset not defined — JPEG DHT memory
  [8n-2041:8n-2048] DATA{n} (n=256..259) — Huffman table data {n} Huffman table data for DHT marker segment generation.
0x464 JPEG_DHTMEM65 reset not defined — JPEG DHT memory
  [8n-2073:8n-2080] DATA{n} (n=260..263) — Huffman table data {n} Huffman table data for DHT marker segment generation.
0x468 JPEG_DHTMEM66 reset not defined — JPEG DHT memory
  [8n-2105:8n-2112] DATA{n} (n=264..267) — Huffman table data {n} Huffman table data for DHT marker segment generation.
0x46C JPEG_DHTMEM67 reset not defined — JPEG DHT memory
  [8n-2137:8n-2144] DATA{n} (n=268..271) — Huffman table data {n} Huffman table data for DHT marker segment generation.
0x470 JPEG_DHTMEM68 reset not defined — JPEG DHT memory
  [8n-2169:8n-2176] DATA{n} (n=272..275) — Huffman table data {n} Huffman table data for DHT marker segment generation.
0x474 JPEG_DHTMEM69 reset not defined — JPEG DHT memory
  [8n-2201:8n-2208] DATA{n} (n=276..279) — Huffman table data {n} Huffman table data for DHT marker segment generation.
0x478 JPEG_DHTMEM70 reset not defined — JPEG DHT memory
  [8n-2233:8n-2240] DATA{n} (n=280..283) — Huffman table data {n} Huffman table data for DHT marker segment generation.
0x47C JPEG_DHTMEM71 reset not defined — JPEG DHT memory
  [8n-2265:8n-2272] DATA{n} (n=284..287) — Huffman table data {n} Huffman table data for DHT marker segment generation.
0x480 JPEG_DHTMEM72 reset not defined — JPEG DHT memory
  [8n-2297:8n-2304] DATA{n} (n=288..291) — Huffman table data {n} Huffman table data for DHT marker segment generation.
0x484 JPEG_DHTMEM73 reset not defined — JPEG DHT memory
  [8n-2329:8n-2336] DATA{n} (n=292..295) — Huffman table data {n} Huffman table data for DHT marker segment generation.
0x488 JPEG_DHTMEM74 reset not defined — JPEG DHT memory
  [8n-2361:8n-2368] DATA{n} (n=296..299) — Huffman table data {n} Huffman table data for DHT marker segment generation.
0x48C JPEG_DHTMEM75 reset not defined — JPEG DHT memory
  [8n-2393:8n-2400] DATA{n} (n=300..303) — Huffman table data {n} Huffman table data for DHT marker segment generation.
0x490 JPEG_DHTMEM76 reset not defined — JPEG DHT memory
  [8n-2425:8n-2432] DATA{n} (n=304..307) — Huffman table data {n} Huffman table data for DHT marker segment generation.
0x494 JPEG_DHTMEM77 reset not defined — JPEG DHT memory
  [8n-2457:8n-2464] DATA{n} (n=308..311) — Huffman table data {n} Huffman table data for DHT marker segment generation.
0x498 JPEG_DHTMEM78 reset not defined — JPEG DHT memory
  [8n-2489:8n-2496] DATA{n} (n=312..315) — Huffman table data {n} Huffman table data for DHT marker segment generation.
0x49C JPEG_DHTMEM79 reset not defined — JPEG DHT memory
  [8n-2521:8n-2528] DATA{n} (n=316..319) — Huffman table data {n} Huffman table data for DHT marker segment generation.
0x4A0 JPEG_DHTMEM80 reset not defined — JPEG DHT memory
  [8n-2553:8n-2560] DATA{n} (n=320..323) — Huffman table data {n} Huffman table data for DHT marker segment generation.
0x4A4 JPEG_DHTMEM81 reset not defined — JPEG DHT memory
  [8n-2585:8n-2592] DATA{n} (n=324..327) — Huffman table data {n} Huffman table data for DHT marker segment generation.
0x4A8 JPEG_DHTMEM82 reset not defined — JPEG DHT memory
  [8n-2617:8n-2624] DATA{n} (n=328..331) — Huffman table data {n} Huffman table data for DHT marker segment generation.
0x4AC JPEG_DHTMEM83 reset not defined — JPEG DHT memory
  [8n-2649:8n-2656] DATA{n} (n=332..335) — Huffman table data {n} Huffman table data for DHT marker segment generation.
0x4B0 JPEG_DHTMEM84 reset not defined — JPEG DHT memory
  [8n-2681:8n-2688] DATA{n} (n=336..339) — Huffman table data {n} Huffman table data for DHT marker segment generation.
0x4B4 JPEG_DHTMEM85 reset not defined — JPEG DHT memory
  [8n-2713:8n-2720] DATA{n} (n=340..343) — Huffman table data {n} Huffman table data for DHT marker segment generation.
0x4B8 JPEG_DHTMEM86 reset not defined — JPEG DHT memory
  [8n-2745:8n-2752] DATA{n} (n=344..347) — Huffman table data {n} Huffman table data for DHT marker segment generation.
0x4BC JPEG_DHTMEM87 reset not defined — JPEG DHT memory
  [8n-2777:8n-2784] DATA{n} (n=348..351) — Huffman table data {n} Huffman table data for DHT marker segment generation.
0x4C0 JPEG_DHTMEM88 reset not defined — JPEG DHT memory
  [8n-2809:8n-2816] DATA{n} (n=352..355) — Huffman table data {n} Huffman table data for DHT marker segment generation.
0x4C4 JPEG_DHTMEM89 reset not defined — JPEG DHT memory
  [8n-2841:8n-2848] DATA{n} (n=356..359) — Huffman table data {n} Huffman table data for DHT marker segment generation.
0x4C8 JPEG_DHTMEM90 reset not defined — JPEG DHT memory
  [8n-2873:8n-2880] DATA{n} (n=360..363) — Huffman table data {n} Huffman table data for DHT marker segment generation.
0x4CC JPEG_DHTMEM91 reset not defined — JPEG DHT memory
  [8n-2905:8n-2912] DATA{n} (n=364..367) — Huffman table data {n} Huffman table data for DHT marker segment generation.
0x4D0 JPEG_DHTMEM92 reset not defined — JPEG DHT memory
  [8n-2937:8n-2944] DATA{n} (n=368..371) — Huffman table data {n} Huffman table data for DHT marker segment generation.
0x4D4 JPEG_DHTMEM93 reset not defined — JPEG DHT memory
  [8n-2969:8n-2976] DATA{n} (n=372..375) — Huffman table data {n} Huffman table data for DHT marker segment generation.
0x4D8 JPEG_DHTMEM94 reset not defined — JPEG DHT memory
  [8n-3001:8n-3008] DATA{n} (n=376..379) — Huffman table data {n} Huffman table data for DHT marker segment generation.
0x4DC JPEG_DHTMEM95 reset not defined — JPEG DHT memory
  [8n-3033:8n-3040] DATA{n} (n=380..383) — Huffman table data {n} Huffman table data for DHT marker segment generation.
0x4E0 JPEG_DHTMEM96 reset not defined — JPEG DHT memory
  [8n-3065:8n-3072] DATA{n} (n=384..387) — Huffman table data {n} Huffman table data for DHT marker segment generation.
0x4E4 JPEG_DHTMEM97 reset not defined — JPEG DHT memory
  [8n-3097:8n-3104] DATA{n} (n=388..391) — Huffman table data {n} Huffman table data for DHT marker segment generation.
0x4E8 JPEG_DHTMEM98 reset not defined — JPEG DHT memory
  [8n-3129:8n-3136] DATA{n} (n=392..395) — Huffman table data {n} Huffman table data for DHT marker segment generation.
0x4EC JPEG_DHTMEM99 reset not defined — JPEG DHT memory
  [8n-3161:8n-3168] DATA{n} (n=396..399) — Huffman table data {n} Huffman table data for DHT marker segment generation.
0x4F0 JPEG_DHTMEM100 reset not defined — JPEG DHT memory
  [8n-3193:8n-3200] DATA{n} (n=400..403) — Huffman table data {n} Huffman table data for DHT marker segment generation.
0x4F4 JPEG_DHTMEM101 reset not defined — JPEG DHT memory
  [8n-3225:8n-3232] DATA{n} (n=404..407) — Huffman table data {n} Huffman table data for DHT marker segment generation.
0x4F8 JPEG_DHTMEM102 reset not defined — JPEG DHT memory
  [8n-3257:8n-3264] DATA{n} (n=408..411) — Huffman table data {n} Huffman table data for DHT marker segment generation.
{0x500+4i} JPEG_HUFFENC_AC0_{i} reset not defined (i=0..87) — JPEG Huffman encoder AC0
  [27:24] HLEN{2i+1} — Huffman length {2i+1} Number of bits in the Huffman code HCODE{2i+1} minus 1.
  [23:16] HCODE{2i+1} — Huffman code {2i+1} 8 least significant bits of the Huffman code. If the Huffman code is less than 8 bits long, the unused bits must be 0.
  [11:8] HLEN{2i} — Huffman length {2i} Number of bits in the Huffman code HCODE{2i} minus 1.
  [7:0] HCODE{2i} — Huffman code {2i} 8 least significant bits of the Huffman code. If the Huffman code is less than 8 bits long, the unused bits must be 0.
{0x5DC+4i} JPEG_HUFFENC_AC1_{i} reset not defined (alternate view of JPEG_HUFFENC_AC0_{i+55}) (i=0..32) — JPEG Huffman encoder AC1
  fields as JPEG_HUFFENC_AC0_0
{0x5DC+4i} JPEG_HUFFENC_AC1_{i} reset not defined (i=33..87) — JPEG Huffman encoder AC1
  fields as JPEG_HUFFENC_AC0_0
{0x7C0+4i} JPEG_HUFFENC_DC0_{i} reset not defined (i=0..7) — JPEG Huffman encoder DC0
  fields as JPEG_HUFFENC_AC0_0
{0x89C+4i} JPEG_HUFFENC_DC1_{i} reset not defined (i=0..7) — JPEG Huffman encoder DC1
  fields as JPEG_HUFFENC_AC0_0
